AUTOSAR XML (schema 4-0-3)
standard types defined: Boolean, UInt32, UInt8
package /AUTOSAR_Platform/DataConstrs
  range DC_Boolean: raw 0..1
  range DC_UInt8: raw 0..255
package /PATAC/Facility/DataTypes/Implementation
  compu method COMPU_Boolean: 0=FALSE, 1=TRUE
  unit NoUnit: factor-si-to-unit=1, offset-si-to-unit=0
package /PATAC/MSM/ComponentTypes
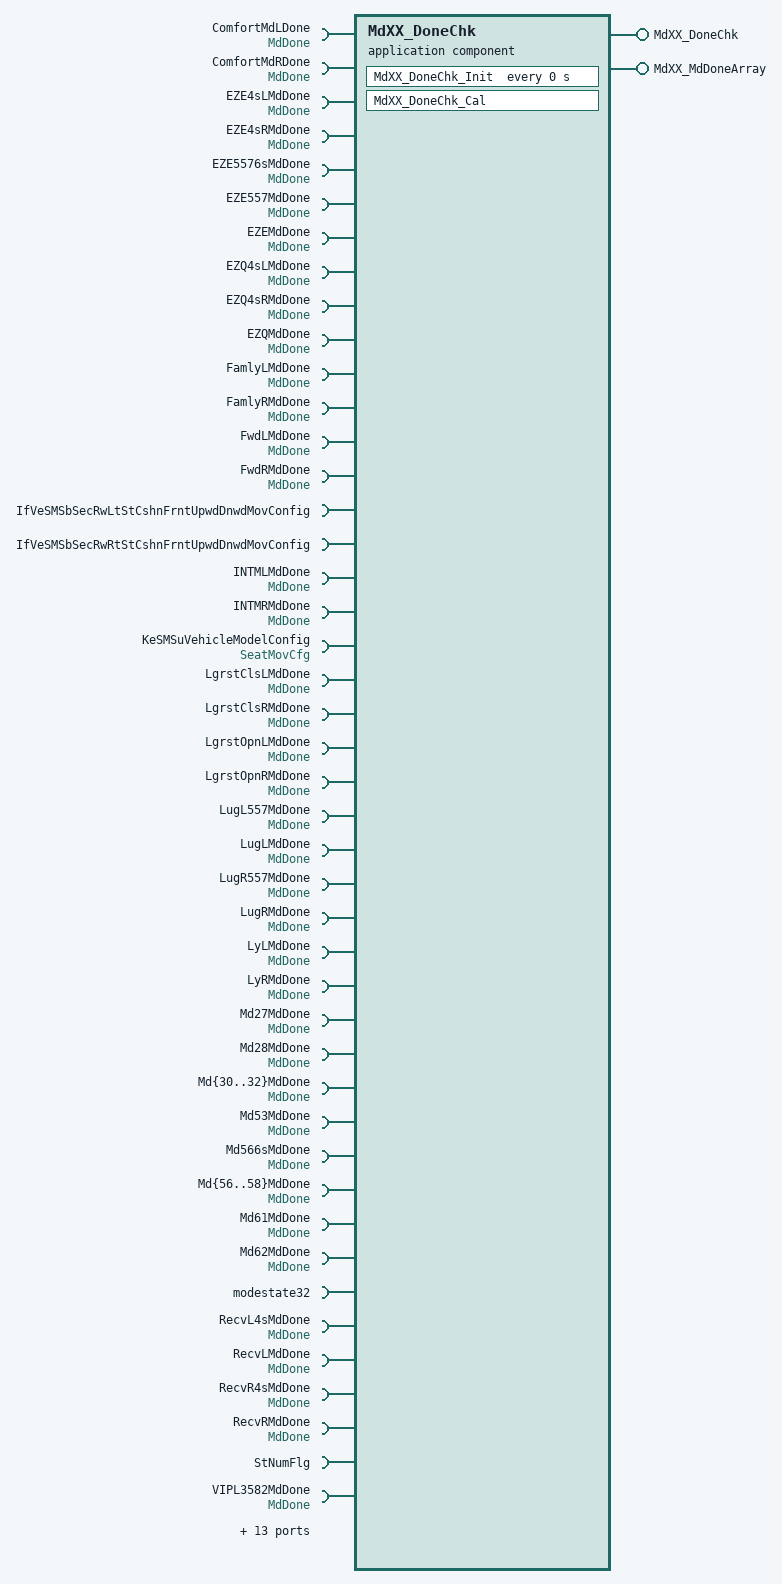
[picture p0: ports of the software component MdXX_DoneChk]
  application sw component type MdXX_DoneChk
    provide port MdXX_DoneChk: server-com-spec{operation=Cal, queue-length=1}, provided-interface=MdXX_DoneChk
    provide port MdXX_MdDoneArray: nonqueued-sender-com-spec=data-element=MdXX_MdDoneArray/Val, provided-interface=MdXX_MdDoneArray
    61 x require port:
      ComfortMdLDone: nonqueued-receiver-com-spec{data-element=MdDone/Val, filter=data-filter-type=ALWAYS, init-value=0}, required-interface=MdDone
      ComfortMdRDone: nonqueued-receiver-com-spec{data-element=MdDone/Val, filter=data-filter-type=ALWAYS, init-value=0}, required-interface=MdDone
      EZE4sLMdDone: nonqueued-receiver-com-spec{data-element=MdDone/Val, filter=data-filter-type=ALWAYS, init-value=0}, required-interface=MdDone
      EZE4sRMdDone: nonqueued-receiver-com-spec{data-element=MdDone/Val, filter=data-filter-type=ALWAYS, init-value=0}, required-interface=MdDone
      EZE5576sMdDone: nonqueued-receiver-com-spec{data-element=MdDone/Val, filter=data-filter-type=ALWAYS, init-value=0}, required-interface=MdDone
      EZE557MdDone: nonqueued-receiver-com-spec{data-element=MdDone/Val, filter=data-filter-type=ALWAYS, init-value=0}, required-interface=MdDone
      EZEMdDone: nonqueued-receiver-com-spec{data-element=MdDone/Val, filter=data-filter-type=ALWAYS, init-value=0}, required-interface=MdDone
      EZQ4sLMdDone: nonqueued-receiver-com-spec{data-element=MdDone/Val, filter=data-filter-type=ALWAYS, init-value=0}, required-interface=MdDone
      EZQ4sRMdDone: nonqueued-receiver-com-spec{data-element=MdDone/Val, filter=data-filter-type=ALWAYS, init-value=0}, required-interface=MdDone
      EZQMdDone: nonqueued-receiver-com-spec{data-element=MdDone/Val, filter=data-filter-type=ALWAYS, init-value=0}, required-interface=MdDone
      FamlyLMdDone: nonqueued-receiver-com-spec{data-element=MdDone/Val, filter=data-filter-type=ALWAYS, init-value=0}, required-interface=MdDone
      FamlyRMdDone: nonqueued-receiver-com-spec{data-element=MdDone/Val, filter=data-filter-type=ALWAYS, init-value=0}, required-interface=MdDone
      FwdLMdDone: nonqueued-receiver-com-spec{data-element=MdDone/Val, filter=data-filter-type=ALWAYS, init-value=0}, required-interface=MdDone
      FwdRMdDone: nonqueued-receiver-com-spec{data-element=MdDone/Val, filter=data-filter-type=ALWAYS, init-value=0}, required-interface=MdDone
      IfVeSMSbSecRwLtStCshnFrntUpwdDnwdMovConfig: nonqueued-receiver-com-spec{data-element=IfVeSMSbSecRwLtStCshnFrntUpwdDnwdMovConfig/Val, filter=data-filter-type=ALWAYS, init-value=0}, required-interface=IfVeSMSbSecRwLtStCshnFrntUpwdDnwdMovConfig
      IfVeSMSbSecRwRtStCshnFrntUpwdDnwdMovConfig: nonqueued-receiver-com-spec{data-element=IfVeSMSbSecRwRtStCshnFrntUpwdDnwdMovConfig/Val, filter=data-filter-type=ALWAYS, init-value=0}, required-interface=IfVeSMSbSecRwRtStCshnFrntUpwdDnwdMovConfig
      INTMLMdDone: nonqueued-receiver-com-spec{data-element=MdDone/Val, filter=data-filter-type=ALWAYS, init-value=0}, required-interface=MdDone
      INTMRMdDone: nonqueued-receiver-com-spec{data-element=MdDone/Val, filter=data-filter-type=ALWAYS, init-value=0}, required-interface=MdDone
      KeSMSuVehicleModelConfig: parameter-require-com-spec{init-value=2, parameter=Val}, required-interface=SeatMovCfg
      LgrstClsLMdDone: nonqueued-receiver-com-spec{data-element=MdDone/Val, filter=data-filter-type=ALWAYS, init-value=0}, required-interface=MdDone
      LgrstClsRMdDone: nonqueued-receiver-com-spec{data-element=MdDone/Val, filter=data-filter-type=ALWAYS, init-value=0}, required-interface=MdDone
      LgrstOpnLMdDone: nonqueued-receiver-com-spec{data-element=MdDone/Val, filter=data-filter-type=ALWAYS, init-value=0}, required-interface=MdDone
      LgrstOpnRMdDone: nonqueued-receiver-com-spec{data-element=MdDone/Val, filter=data-filter-type=ALWAYS, init-value=0}, required-interface=MdDone
      LugL557MdDone: nonqueued-receiver-com-spec{data-element=MdDone/Val, filter=data-filter-type=ALWAYS, init-value=0}, required-interface=MdDone
      LugLMdDone: nonqueued-receiver-com-spec{data-element=MdDone/Val, filter=data-filter-type=ALWAYS, init-value=0}, required-interface=MdDone
      LugR557MdDone: nonqueued-receiver-com-spec{data-element=MdDone/Val, filter=data-filter-type=ALWAYS, init-value=0}, required-interface=MdDone
      LugRMdDone: nonqueued-receiver-com-spec{data-element=MdDone/Val, filter=data-filter-type=ALWAYS, init-value=0}, required-interface=MdDone
      LyLMdDone: nonqueued-receiver-com-spec{data-element=MdDone/Val, filter=data-filter-type=ALWAYS, init-value=0}, required-interface=MdDone
      LyRMdDone: nonqueued-receiver-com-spec{data-element=MdDone/Val, filter=data-filter-type=ALWAYS, init-value=0}, required-interface=MdDone
      Md27MdDone: nonqueued-receiver-com-spec{data-element=MdDone/Val, filter=data-filter-type=ALWAYS, init-value=0}, required-interface=MdDone
      Md28MdDone: nonqueued-receiver-com-spec{data-element=MdDone/Val, filter=data-filter-type=ALWAYS, init-value=0}, required-interface=MdDone
      Md{30..32}MdDone: nonqueued-receiver-com-spec{data-element=MdDone/Val, filter=data-filter-type=ALWAYS, init-value=0}, required-interface=MdDone
      Md53MdDone: nonqueued-receiver-com-spec{data-element=MdDone/Val, filter=data-filter-type=ALWAYS, init-value=0}, required-interface=MdDone
      Md566sMdDone: nonqueued-receiver-com-spec{data-element=MdDone/Val, filter=data-filter-type=ALWAYS, init-value=0}, required-interface=MdDone
      Md{56..58}MdDone: nonqueued-receiver-com-spec{data-element=MdDone/Val, filter=data-filter-type=ALWAYS, init-value=0}, required-interface=MdDone
      Md61MdDone: nonqueued-receiver-com-spec{data-element=MdDone/Val, filter=data-filter-type=ALWAYS, init-value=0}, required-interface=MdDone
      Md62MdDone: nonqueued-receiver-com-spec{data-element=MdDone/Val, filter=data-filter-type=ALWAYS, init-value=0}, required-interface=MdDone
      modestate32: nonqueued-receiver-com-spec{data-element=modestate32/Val, filter=data-filter-type=ALWAYS, init-value=0}, required-interface=modestate32
      RecvL4sMdDone: nonqueued-receiver-com-spec{data-element=MdDone/Val, filter=data-filter-type=ALWAYS, init-value=0}, required-interface=MdDone
      RecvLMdDone: nonqueued-receiver-com-spec{data-element=MdDone/Val, filter=data-filter-type=ALWAYS, init-value=0}, required-interface=MdDone
      RecvR4sMdDone: nonqueued-receiver-com-spec{data-element=MdDone/Val, filter=data-filter-type=ALWAYS, init-value=0}, required-interface=MdDone
      RecvRMdDone: nonqueued-receiver-com-spec{data-element=MdDone/Val, filter=data-filter-type=ALWAYS, init-value=0}, required-interface=MdDone
      StNumFlg: required-interface=StNumFlg
        required-com-specs:
          data-element=Is4s, filter=data-filter-type=ALWAYS, init-value=0
          data-element=Is6s, filter=data-filter-type=ALWAYS, init-value=0
          data-element=Is6s7s, filter=data-filter-type=ALWAYS, init-value=0
          data-element=Is7s, filter=data-filter-type=ALWAYS, init-value=0
      VIPL3582MdDone: nonqueued-receiver-com-spec{data-element=MdDone/Val, filter=data-filter-type=ALWAYS, init-value=0}, required-interface=MdDone
      VIPL4sMdDone: nonqueued-receiver-com-spec{data-element=MdDone/Val, filter=data-filter-type=ALWAYS, init-value=0}, required-interface=MdDone
      VIPL557LTMdDone: nonqueued-receiver-com-spec{data-element=MdDone/Val, filter=data-filter-type=ALWAYS, init-value=0}, required-interface=MdDone
      VIPL557MdDone: nonqueued-receiver-com-spec{data-element=MdDone/Val, filter=data-filter-type=ALWAYS, init-value=0}, required-interface=MdDone
      VIPLExit557MdDone: nonqueued-receiver-com-spec{data-element=MdDone/Val, filter=data-filter-type=ALWAYS, init-value=0}, required-interface=MdDone
      VIPLMdDone: nonqueued-receiver-com-spec{data-element=MdDone/Val, filter=data-filter-type=ALWAYS, init-value=0}, required-interface=MdDone
      VIPR3582MdDone: nonqueued-receiver-com-spec{data-element=MdDone/Val, filter=data-filter-type=ALWAYS, init-value=0}, required-interface=MdDone
      VIPR4sMdDone: nonqueued-receiver-com-spec{data-element=MdDone/Val, filter=data-filter-type=ALWAYS, init-value=0}, required-interface=MdDone
      VIPR557LTMdDone: nonqueued-receiver-com-spec{data-element=MdDone/Val, filter=data-filter-type=ALWAYS, init-value=0}, required-interface=MdDone
      VIPR557MdDone: nonqueued-receiver-com-spec{data-element=MdDone/Val, filter=data-filter-type=ALWAYS, init-value=0}, required-interface=MdDone
      VIPRExit557MdDone: nonqueued-receiver-com-spec{data-element=MdDone/Val, filter=data-filter-type=ALWAYS, init-value=0}, required-interface=MdDone
      VIPRMdDone: nonqueued-receiver-com-spec{data-element=MdDone/Val, filter=data-filter-type=ALWAYS, init-value=0}, required-interface=MdDone
      WelcomeBkwdMdDone: nonqueued-receiver-com-spec{data-element=MdDone/Val, filter=data-filter-type=ALWAYS, init-value=0}, required-interface=MdDone
      WelcomeFwdMdDone: nonqueued-receiver-com-spec{data-element=MdDone/Val, filter=data-filter-type=ALWAYS, init-value=0}, required-interface=MdDone
    behavior MdXX_DoneChk_InternalBehavior
      operation invoked event OIT_MdXX_DoneChk_Cal_MdXX_DoneChk_Cal: start-on-event=MdXX_DoneChk_Cal, operation=MdXX_DoneChk.Cal
      timing event MdXX_DoneChk_InitEvent: start-on-event=MdXX_DoneChk_Init, period=0
      runnable MdXX_DoneChk_Cal
        data-receive-point-by-arguments:
          63 x access:
            REC_ComfortMdLDone_Val: accessed-variable=ComfortMdLDone.Val
            REC_ComfortMdRDone_Val: accessed-variable=ComfortMdRDone.Val
            REC_EZE4sLMdDone_Val: accessed-variable=EZE4sLMdDone.Val
            REC_EZE4sRMdDone_Val: accessed-variable=EZE4sRMdDone.Val
            REC_EZE5576sMdDone_Val: accessed-variable=EZE5576sMdDone.Val
            REC_EZE557MdDone_Val: accessed-variable=EZE557MdDone.Val
            REC_EZEMdDone_Val: accessed-variable=EZEMdDone.Val
            REC_EZQ4sLMdDone_Val: accessed-variable=EZQ4sLMdDone.Val
            REC_EZQ4sRMdDone_Val: accessed-variable=EZQ4sRMdDone.Val
            REC_EZQMdDone_Val: accessed-variable=EZQMdDone.Val
            REC_FamlyLMdDone_Val: accessed-variable=FamlyLMdDone.Val
            REC_FamlyRMdDone_Val: accessed-variable=FamlyRMdDone.Val
            REC_FwdLMdDone_Val: accessed-variable=FwdLMdDone.Val
            REC_FwdRMdDone_Val: accessed-variable=FwdRMdDone.Val
            REC_IfVeSMSbSecRwLtStCshnFrntUpwdDnwdMovConfig_Val: accessed-variable=IfVeSMSbSecRwLtStCshnFrntUpwdDnwdMovConfig.Val
            REC_IfVeSMSbSecRwRtStCshnFrntUpwdDnwdMovConfig_Val: accessed-variable=IfVeSMSbSecRwRtStCshnFrntUpwdDnwdMovConfig.Val
            REC_INTMLMdDone_Val: accessed-variable=INTMLMdDone.Val
            REC_INTMRMdDone_Val: accessed-variable=INTMRMdDone.Val
            REC_LgrstClsLMdDone_Val: accessed-variable=LgrstClsLMdDone.Val
            REC_LgrstClsRMdDone_Val: accessed-variable=LgrstClsRMdDone.Val
            REC_LgrstOpnLMdDone_Val: accessed-variable=LgrstOpnLMdDone.Val
            REC_LgrstOpnRMdDone_Val: accessed-variable=LgrstOpnRMdDone.Val
            REC_LugL557MdDone_Val: accessed-variable=LugL557MdDone.Val
            REC_LugLMdDone_Val: accessed-variable=LugLMdDone.Val
            REC_LugR557MdDone_Val: accessed-variable=LugR557MdDone.Val
            REC_LugRMdDone_Val: accessed-variable=LugRMdDone.Val
            REC_LyLMdDone_Val: accessed-variable=LyLMdDone.Val
            REC_LyRMdDone_Val: accessed-variable=LyRMdDone.Val
            REC_Md27MdDone_Val: accessed-variable=Md27MdDone.Val
            REC_Md28MdDone_Val: accessed-variable=Md28MdDone.Val
            REC_Md{30..32}MdDone_Val: accessed-variable=Md{30..32}MdDone.Val
            REC_Md53MdDone_Val: accessed-variable=Md53MdDone.Val
            REC_Md566sMdDone_Val: accessed-variable=Md566sMdDone.Val
            REC_Md{56..58}MdDone_Val: accessed-variable=Md{56..58}MdDone.Val
            REC_Md61MdDone_Val: accessed-variable=Md61MdDone.Val
            REC_Md62MdDone_Val: accessed-variable=Md62MdDone.Val
            REC_modestate32_Val: accessed-variable=modestate32.Val
            REC_RecvL4sMdDone_Val: accessed-variable=RecvL4sMdDone.Val
            REC_RecvLMdDone_Val: accessed-variable=RecvLMdDone.Val
            REC_RecvR4sMdDone_Val: accessed-variable=RecvR4sMdDone.Val
            REC_RecvRMdDone_Val: accessed-variable=RecvRMdDone.Val
            REC_StNumFlg_Is4s: accessed-variable=StNumFlg.Is4s
            REC_StNumFlg_Is6s: accessed-variable=StNumFlg.Is6s
            REC_StNumFlg_Is6s7s: accessed-variable=StNumFlg.Is6s7s
            REC_StNumFlg_Is7s: accessed-variable=StNumFlg.Is7s
            REC_VIPL3582MdDone_Val: accessed-variable=VIPL3582MdDone.Val
            REC_VIPL4sMdDone_Val: accessed-variable=VIPL4sMdDone.Val
            REC_VIPL557LTMdDone_Val: accessed-variable=VIPL557LTMdDone.Val
            REC_VIPL557MdDone_Val: accessed-variable=VIPL557MdDone.Val
            REC_VIPLExit557MdDone_Val: accessed-variable=VIPLExit557MdDone.Val
            REC_VIPLMdDone_Val: accessed-variable=VIPLMdDone.Val
            REC_VIPR3582MdDone_Val: accessed-variable=VIPR3582MdDone.Val
            REC_VIPR4sMdDone_Val: accessed-variable=VIPR4sMdDone.Val
            REC_VIPR557LTMdDone_Val: accessed-variable=VIPR557LTMdDone.Val
            REC_VIPR557MdDone_Val: accessed-variable=VIPR557MdDone.Val
            REC_VIPRExit557MdDone_Val: accessed-variable=VIPRExit557MdDone.Val
            REC_VIPRMdDone_Val: accessed-variable=VIPRMdDone.Val
            REC_WelcomeBkwdMdDone_Val: accessed-variable=WelcomeBkwdMdDone.Val
            REC_WelcomeFwdMdDone_Val: accessed-variable=WelcomeFwdMdDone.Val
        data-send-points:
          access SEND_MdXX_MdDoneArray_Val: accessed-variable=MdXX_MdDoneArray.Val
        parameter access PA_KeSMSuVehicleModelConfig_Val: accessed-parameter=KeSMSuVehicleModelConfig.Val
      runnable MdXX_DoneChk_Init
        parameter access PA_KeSMSuVehicleModelConfig_Val: accessed-parameter=KeSMSuVehicleModelConfig.Val
  swc implementation MdXX_DoneChk_Implementation: behavior=MdXX_DoneChk_InternalBehavior
    code-descriptors:
      code Default: artifact-descriptors=autosar-engineering-object={short-label=Default, category=SWSRC}
package /PATAC/MSM/DataTypes
  parameter interface SeatMovCfg
    parameter data prototype Val: sw-calibration-access=READ-WRITE, type=UInt8
package /PATAC/MSM/ModeAdjust/DataType
  impl type Array1x32_Uint8: category=ARRAY, sw-calibration-access=READ-ONLY, type-emitter=RTE
    element Element: array-size=32, array-size-semantics=FIXED-SIZE, implementation-data-type=UInt8
package /PATAC/MSM/ModeAdjust/PortInterface
  client server interface MdXX_DoneChk
    operation Cal
  4 x sender receiver interface:
    MdDone: invalidation-policy{data-element=MdDone/Val, handle-invalid=DONT-INVALIDATE}
      data Val: type=UInt8
    MdXX_MdDoneArray: invalidation-policy{data-element=MdXX_MdDoneArray/Val, handle-invalid=DONT-INVALIDATE}
      data Val: type=Array1x32_Uint8
    modestate32: invalidation-policy{data-element=modestate32/Val, handle-invalid=DONT-INVALIDATE}
      data Val: type=UInt32
    StNumFlg
      4 x data, all with type=Boolean:
        Is4s
        Is6s
        Is6s7s
        Is7s
      invalidation-policys:
        data-element=Is4s, handle-invalid=DONT-INVALIDATE
        data-element=Is6s, handle-invalid=DONT-INVALIDATE
        data-element=Is6s7s, handle-invalid=DONT-INVALIDATE
        data-element=Is7s, handle-invalid=DONT-INVALIDATE
package /PATAC/MSM/PortInterfaces
  sender receiver interface IfVeSMSbSecRwLtStCshnFrntUpwdDnwdMovConfig: invalidation-policy{data-element=IfVeSMSbSecRwLtStCshnFrntUpwdDnwdMovConfig/Val, handle-invalid=DONT-INVALIDATE}
    data Val: type=Boolean
  sender receiver interface IfVeSMSbSecRwRtStCshnFrntUpwdDnwdMovConfig: invalidation-policy{data-element=IfVeSMSbSecRwRtStCshnFrntUpwdDnwdMovConfig/Val, handle-invalid=DONT-INVALIDATE}
    data Val: type=Boolean
